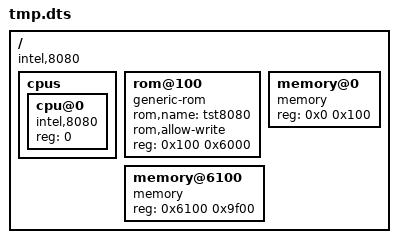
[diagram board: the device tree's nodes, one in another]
/dts-v1/;

/ {
	compatible = "intel,8080";
	#address-cells = <1>;
	#size-cells = <1>;

	cpus {
		#address-cells = <1>;
		#size-cells = <0>;
		cpu@0 {
			device_type = "cpu";
			compatible = "intel,8080";
			reg = <0>;
			//dtemu,override-reset-vector = <0xff00>;
		};
	};

	rom@100 {
		compatible = "generic-rom";
		rom,name = "tst8080";
		rom,allow-write;
		reg = <0x100 0x6000>;
	};

	memory@0 {
		compatible = "memory";
		reg = <0x0 0x100>;
	};

	memory@6100 {
		compatible = "memory";
		reg = <0x6100 0x9f00>;
	};
};
